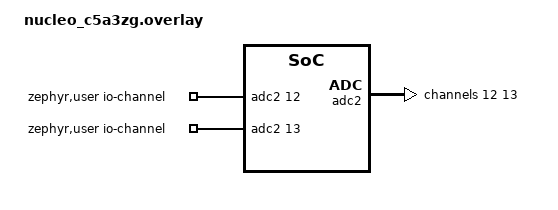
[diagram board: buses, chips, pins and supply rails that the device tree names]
/*
 * SPDX-License-Identifier: Apache-2.0
 *
 * Copyright (c) 2026 STMicroelectronics
 */

/ {
	zephyr,user {
		/* adjust channel number according to pinmux in board.dts */
		io-channels = <&adc2 12>, <&adc2 13>;
	};
};

&adc2 {
	dmas = <&lpdma1 0 1 (STM32_DMA_PERIPH_RX | STM32_DMA_MEM_16BITS | STM32_DMA_PERIPH_16BITS)>;
	dma-names = "lpdma";

	#address-cells = <1>;
	#size-cells = <0>;

	channel@c {
		reg = <12>;
		zephyr,gain = "ADC_GAIN_1";
		zephyr,reference = "ADC_REF_INTERNAL";
		zephyr,acquisition-time = <ADC_ACQ_TIME_MAX>;
		zephyr,resolution = <12>;
	};

	channel@d {
		reg = <13>;
		zephyr,gain = "ADC_GAIN_1";
		zephyr,reference = "ADC_REF_INTERNAL";
		zephyr,acquisition-time = <ADC_ACQ_TIME_MAX>;
		zephyr,resolution = <12>;
	};
};

&lpdma1 {
	status = "okay";
};
